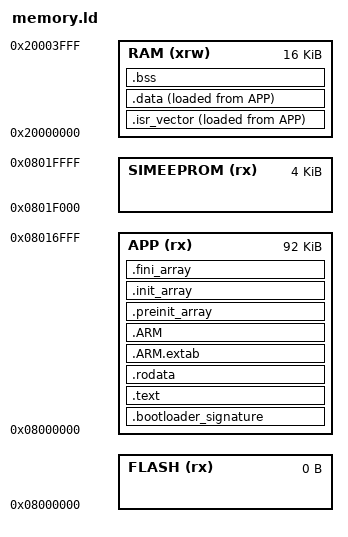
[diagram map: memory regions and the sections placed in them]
/*
******************************************************************************
**
** @file        : LinkerScript.ld
**
** @author      : Auto-generated by STM32CubeIDE
**
** @brief       : Linker script for STM32F072CBTx Device from STM32F0 series
**                      128Kbytes FLASH
**                      16Kbytes RAM
**
**                Set heap size, stack size and stack location according
**                to application requirements.
**
**                Set memory bank area and size if external memory is used
**
**  Target      : STMicroelectronics STM32
**
**  Distribution: The file is distributed as is, without any warranty
**                of any kind.
**
******************************************************************************
** @attention
**
** Copyright (c) 2022 STMicroelectronics.
** All rights reserved.
**
** This software is licensed under terms that can be found in the LICENSE file
** in the root directory of this software component.
** If no LICENSE file comes with this software, it is provided AS-IS.
**
******************************************************************************
*/

/* Entry Point */
ENTRY(Reset_Handler)

_Min_Heap_Size = DEFINED(HEAP_SIZE) ? HEAP_SIZE : 0x200; /* required amount of heap */
_Min_Stack_Size = DEFINED(STACK_SIZE) ? STACK_SIZE : 0x400; /* required amount of stack */
/* Highest address of the user mode stack */
_estack = ORIGIN(RAM) + LENGTH(RAM); /* end of "RAM" Ram type memory */
__flash_start__ = ORIGIN(FLASH);
__flash_size__ = 128K;
__flash_page_size__ = 2K;

__bootloader_start__ = ORIGIN(FLASH);
__bootloader_size__ = LENGTH(FLASH);

__application_start__ = ORIGIN(APP);
__update_bank_start__ = ORIGIN(APP);
__update_bank_end__ = ORIGIN(APP) + LENGTH(APP);

__simeeprom_bank_start__ = ORIGIN(SIMEEPROM);
__simeeprom_bank_end__ = ORIGIN(SIMEEPROM) + LENGTH(SIMEEPROM);
__simeeprom_bank_size__ = LENGTH(SIMEEPROM);

__regions_size__ = LENGTH(FLASH) + LENGTH(APP) + LENGTH(SIMEEPROM);
ASSERT((__regions_size__) <= 128K, "Memory regions allocates more memory than available");


/* Memories definition */
MEMORY
{
  RAM         (xrw)   : ORIGIN = 0x20000000,   LENGTH = 16K
  FLASH       (rx)    : ORIGIN = 0x08000000,   LENGTH = 0K
  APP         (rx)    : ORIGIN = 0x08000000,   LENGTH = 92K
  SIMEEPROM   (rx)    : ORIGIN = 0x0801F000,   LENGTH = 4K
}

/* Sections */
SECTIONS
{
  /* The startup code into "FLASH" Rom type memory */
  .isr_vector : ALIGN(1024)
  {
    __vector_start__ = .;
    KEEP(*(.isr_vector)) /* Startup code */
    __vector_end__ = .;
  } >RAM AT> APP

  __vector_copy_start__ = LOADADDR(.isr_vector);
  __vector_copy_size__ = SIZEOF(.isr_vector);

  .bootloader_signature : ALIGN(256)
  {
    KEEP(*(.bootloader_signature .bootloader_signature*))
  } > APP

  /* The program code and other data into "FLASH" Rom type memory */
  .text :
  {
    . = ALIGN(4);
    *(.text)           /* .text sections (code) */
    *(.text*)          /* .text* sections (code) */
    *(.glue_7)         /* glue arm to thumb code */
    *(.glue_7t)        /* glue thumb to arm code */
    *(.eh_frame)

    KEEP (*(.init))
    KEEP (*(.fini))

    . = ALIGN(4);
    _etext = .;        /* define a global symbols at end of code */
  } >APP

  /* Constant data into "FLASH" Rom type memory */
  .rodata :
  {
    . = ALIGN(4);
    *(.rodata)         /* .rodata sections (constants, strings, etc.) */
    *(.rodata*)        /* .rodata* sections (constants, strings, etc.) */
    . = ALIGN(4);
  } >APP

  .ARM.extab   : {
    . = ALIGN(4);
    *(.ARM.extab* .gnu.linkonce.armextab.*)
    . = ALIGN(4);
  } >APP

  .ARM : {
    . = ALIGN(4);
    __exidx_start = .;
    *(.ARM.exidx*)
    __exidx_end = .;
    . = ALIGN(4);
  } >APP

  .preinit_array     :
  {
    . = ALIGN(4);
    PROVIDE_HIDDEN (__preinit_array_start = .);
    KEEP (*(.preinit_array*))
    PROVIDE_HIDDEN (__preinit_array_end = .);
    . = ALIGN(4);
  } >APP

  .init_array :
  {
    . = ALIGN(4);
    PROVIDE_HIDDEN (__init_array_start = .);
    KEEP (*(SORT(.init_array.*)))
    KEEP (*(.init_array*))
    PROVIDE_HIDDEN (__init_array_end = .);
    . = ALIGN(4);
  } >APP

  .fini_array :
  {
    . = ALIGN(4);
    PROVIDE_HIDDEN (__fini_array_start = .);
    KEEP (*(SORT(.fini_array.*)))
    KEEP (*(.fini_array*))
    PROVIDE_HIDDEN (__fini_array_end = .);
    . = ALIGN(4);
  } >APP

  /* Used by the startup to initialize data */
  _sidata = LOADADDR(.data);

  /* Initialized data sections into "RAM" Ram type memory */
  .data : ALIGN(4)
  {
    . = ALIGN(4);
    _sdata = .;        /* create a global symbol at data start */
    *(.data)           /* .data sections */
    *(.data*)          /* .data* sections */
    *(.RamFunc)        /* .RamFunc sections */
    *(.RamFunc*)       /* .RamFunc* sections */

    . = ALIGN(4);
    _edata = .;        /* define a global symbol at data end */

  } >RAM AT> APP

  __end_of_firmware__ = ALIGN(_sidata + SIZEOF(.data), 4);

  /* Uninitialized data section into "RAM" Ram type memory */
  . = ALIGN(4);
  .bss (NOLOAD) : ALIGN(4)
  {
    /* This is used by the startup in order to initialize the .bss section */
    _sbss = .;         /* define a global symbol at bss start */
    __bss_start__ = _sbss;
    *(.bss)
    *(.bss*)
    *(COMMON)

    . = ALIGN(4);
    _ebss = .;         /* define a global symbol at bss end */
    __bss_end__ = _ebss;
    __heap_start__ = ALIGN(__bss_end__, 4);
  } >RAM

  /* Remove information from the compiler libraries */
  /DISCARD/ :
  {
    libc.a ( * )
    libm.a ( * )
    libgcc.a ( * )
  }

  .ARM.attributes 0 : { *(.ARM.attributes) }
}

ASSERT(_estack == ALIGN(_estack, 8), "Stack boundary is not aligned to 8 bytes");
ASSERT((ALIGN(__bss_end__, 4) + ALIGN(_Min_Heap_Size, 4)) <= (_estack - _Min_Stack_Size), "BSS with heap region overlaps stack");
